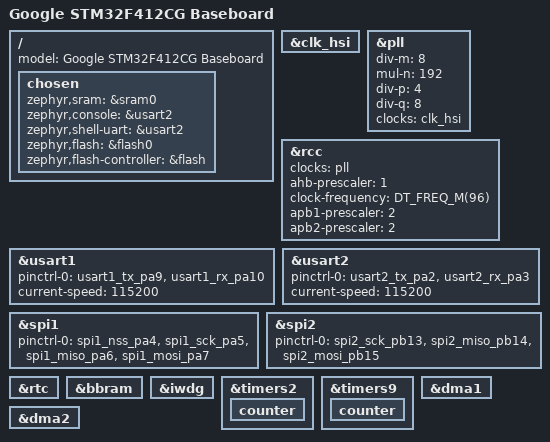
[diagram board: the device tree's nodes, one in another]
/* Copyright 2021 The Chromium OS Authors. All rights reserved.
 * Use of this source code is governed by a BSD-style license that can be
 * found in the LICENSE file.
 */

/dts-v1/;

#include <cros/st/stm32f4.dtsi>
#include <dt-bindings/gpio_defines.h>
#include <st/f4/stm32f412z(e-g)tx-pinctrl.dtsi>
#include <st/f4/stm32f412Xg.dtsi>

/ {
	model = "Google STM32F412CG Baseboard";

	chosen {
		zephyr,sram = &sram0;
		zephyr,console = &usart2;
		zephyr,shell-uart = &usart2;
		zephyr,flash = &flash0;
		zephyr,flash-controller = &flash;
	};
};

&clk_hsi {
	/* HSI clock frequency is 16Mhz */
	status = "okay";
};

&pll {
	div-m = <8>;
	mul-n = <192>; /* 16Mhz * 192/8 = 384Mhz VCO clock */
	div-p = <4>; /* 96Mhz PLL general clock output */
	div-q = <8>; /* 48Mhz PLL output for USB, SDIO, RNG */
	clocks = <&clk_hsi>;
	status = "okay";
};

&rcc {
	clocks = <&pll>; /* Select PLL as SYSCLK source (96Mhz) */
	ahb-prescaler = <1>; /* SYSCLK not divided */
	clock-frequency = <DT_FREQ_M(96)>; /* AHB frequency */
	apb1-prescaler = <2>; /* AHB clock divided by 2 */
	apb2-prescaler = <2>; /* AHB clock divided by 2 */
};

/* USART1: PA9/PA10 (TX/RX) to AP (Host Commands and MKBP) */
&usart1 {
	pinctrl-0 = <&usart1_tx_pa9 &usart1_rx_pa10>;
	pinctrl-names = "default";
	current-speed = <115200>;
	status = "okay";
};

/* USART2: PA2/PA3 (TX/RX) to servo (console) */
&usart2 {
	pinctrl-0 = <&usart2_tx_pa2 &usart2_rx_pa3>;
	pinctrl-names = "default";
	current-speed = <115200>;
	status = "okay";
};

/* SPI1: communication with the AP PA4/5/6/7 (CS/CLK/MISO/MOSI) */
&spi1 {
	pinctrl-0 = <&spi1_nss_pa4 &spi1_sck_pa5
		     &spi1_miso_pa6 &spi1_mosi_pa7>;
	pinctrl-names = "default";
	status = "okay";
};

/* SPI2: communication with the sensor PB13/14/15 (CLK/MISO/MOSI) */
&spi2 {
	pinctrl-0 = <&spi2_sck_pb13 &spi2_miso_pb14
	             &spi2_mosi_pb15>;
	pinctrl-names = "default";
	status = "okay";
};

&rtc {
	status = "okay";
};

&bbram {
	status = "okay";
};

&iwdg {
	status = "okay";
};

&timers2 {
	status = "okay";
	counter {
		status = "okay";
	};
};

&timers9 {
	status = "okay";
	counter {
		status = "okay";
	};
};

&dma1 {
	status = "okay";
};

&dma2 {
	status = "okay";
};
